VERSION ""

NS_ :

BS_:

BU_:

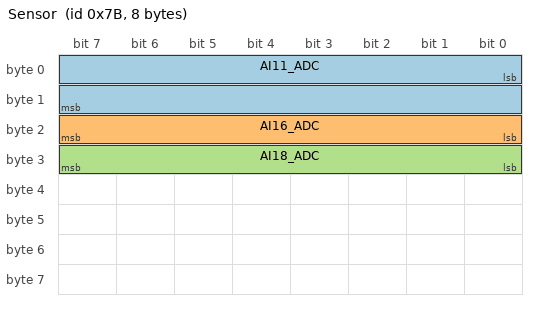
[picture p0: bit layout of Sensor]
BO_ 123 Sensor: 8 Vector__XXX
 SG_ AI11_ADC : 0|16@1+ (1,0) [0|0] "" Vector__XXX
 SG_ AI16_ADC : 16|8@1+ (1,0) [0|0] "" Vector__XXX
 SG_ AI18_ADC : 24|8@1+ (1,0) [0|0] "" Vector__XXX

BA_DEF_  "BusType" STRING ;
BA_DEF_DEF_  "BusType" "CAN";
